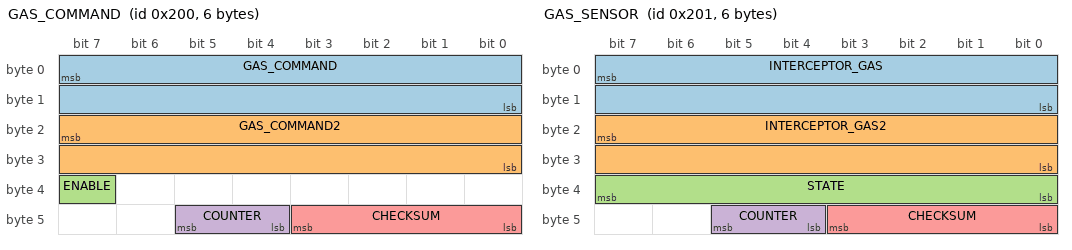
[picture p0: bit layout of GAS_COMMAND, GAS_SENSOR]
BO_ 512 GAS_COMMAND: 6 EON
 SG_ GAS_COMMAND : 7|16@0+ (0.253984064,-83.3) [0|1] "" INTERCEPTOR
 SG_ GAS_COMMAND2 : 23|16@0+ (0.126992032,-83.3) [0|1] "" INTERCEPTOR
 SG_ ENABLE : 39|1@0+ (1,0) [0|1] "" INTERCEPTOR
 SG_ COUNTER : 45|2@0+ (1,0) [0|3] "" INTERCEPTOR
 SG_ CHECKSUM : 43|4@0+ (1,0) [0|3] "" INTERCEPTOR

BO_ 513 GAS_SENSOR: 6 INTERCEPTOR
 SG_ INTERCEPTOR_GAS : 7|16@0+ (0.253984064,-83.3) [0|1] "" EON
 SG_ INTERCEPTOR_GAS2 : 23|16@0+ (0.126992032,-83.3) [0|1] "" EON
 SG_ STATE : 39|8@0+ (1,0) [0|255] "" EON
 SG_ COUNTER : 45|2@0+ (1,0) [0|3] "" EON
 SG_ CHECKSUM : 43|4@0+ (1,0) [0|3] "" EON
